# M365 register map
File version: 0.1
TOSHIBA Cortex-M3 MCU
CPU: 
Registers are 32-bit, read-write, reset 0x0 unless marked. A register's access mark holds for its fields unless they carry their own. Offsets are from the block's base; lines under a group give offsets from that group; [hi:lo] are bit positions; {n}, {i} and the like mark numbered series; 'fields as' and 'values as' point back to an identical list; <NAME> marks a mode.

## Memory map
0x40000000 DMAC size 0x28 — DMA Controller
0x40008000 UDFS size 0x24 — UDC2 AHB Bridge
0x40008200 UDFS2 size 0x8 — UDC2(USB -Spec2.0 Device contoller)
0x40050000 AD size 0x64 — Analog-to-Digital Converter (AD)
0x400C0000 PA size 0x8 — General Purpose Input_Output Port (PA)
0x400C0100 PB size 0x8 — General Purpose Input_Output Port (PB)
0x400C0200 PC size 0xC — General Purpose Input_Output Port (PC)
0x400C0300 PD size 0x8 — General Purpose Input_Output Port (PD)
0x400C0400 PE size 0xC — General Purpose Input_Output Port (PE)
0x400C0500 PF size 0x8 — General Purpose Input_Output Port (PF)
0x400C0600 PG size 0xC — General Purpose Input_Output Port (PG)
0x400C0700 PH size 0xC — General Purpose Input_Output Port (PH)
0x400C0800 PI size 0x8 — General Purpose Input_Output Port (PI)
0x400C0900 PJ size 0x8 — General Purpose Input_Output Port (PJ)
0x400C0A00 PK size 0x8 — General Purpose Input_Output Port (PK)
{0x400C4000+0x100*n} TB{n} size 0x34 (n=0..9) — 16-bit Timer_Event Counter (TB)
0x400E0000 SBI0 size 0x18 — Serial Bus Interface (SBI)
0x400E0100 SBI1 size 0x18 — Serial Bus Interface (SBI)
0x400E1000 SC0 size 0x38 — Serial Channel (SC)
0x400E1100 SC1 size 0x38 — Serial Channel (SC)
0x400F2000 WD size 0x8 — Watchdog Timer (WD)
0x400F3000 CG size 0x14 — Clock Generator (CG)
0x41FFF010 FC size 0x4 — Flash Control (FC)

## DMAC — DMA Controller
Base 0x40000000
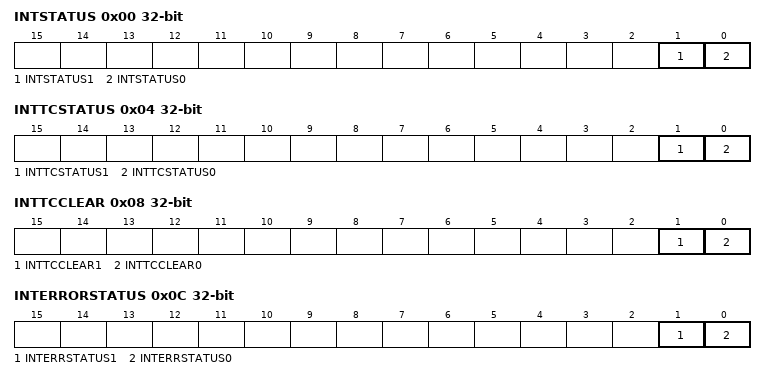
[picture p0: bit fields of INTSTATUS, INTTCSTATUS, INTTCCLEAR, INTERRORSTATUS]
0x00 INTSTATUS ro — DMAC Interrupt Status Register
  [1] INTSTATUS1, [0] INTSTATUS0
0x04 INTTCSTATUS ro — DMAC Interrupt Terminal Count Status Register
  [1] INTTCSTATUS1, [0] INTTCSTATUS0
0x08 INTTCCLEAR wo — DMAC Interrupt Terminal Count Clear Register
  [1] INTTCCLEAR1, [0] INTTCCLEAR0
0x0C INTERRORSTATUS ro — DMAC Interrupt Error Status Register
  [1] INTERRSTATUS1, [0] INTERRSTATUS0
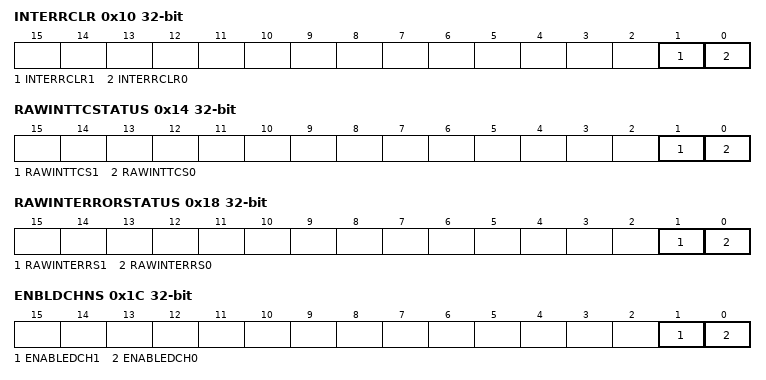
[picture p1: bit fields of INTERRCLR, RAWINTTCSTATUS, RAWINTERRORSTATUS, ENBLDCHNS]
0x10 INTERRCLR wo — DMAC Interrupt Error Clear Register
  [1] INTERRCLR1, [0] INTERRCLR0
0x14 RAWINTTCSTATUS ro — DMAC Raw Interrupt Terminal Count Status Register
  [1] RAWINTTCS1, [0] RAWINTTCS0
0x18 RAWINTERRORSTATUS ro — DMAC Raw Error Interrupt Status Register
  [1] RAWINTERRS1, [0] RAWINTERRS0
0x1C ENBLDCHNS ro — DMAC Enabled Channel Register
  [1] ENABLEDCH1, [0] ENABLEDCH0
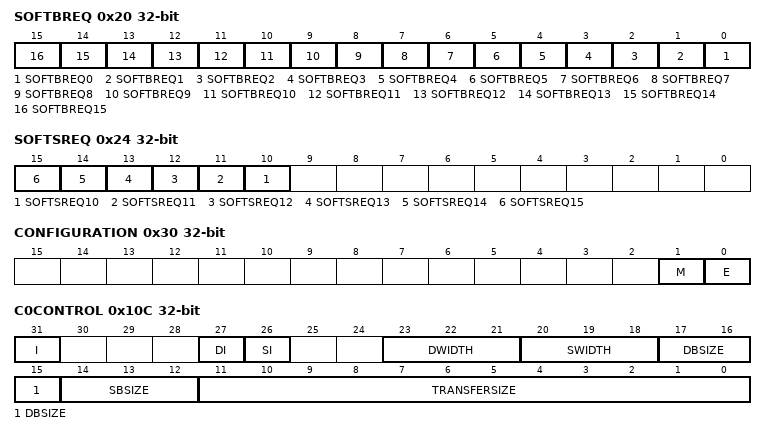
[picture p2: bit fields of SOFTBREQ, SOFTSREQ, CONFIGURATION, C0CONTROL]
0x20 SOFTBREQ — DMAC Software Burst Request Register
  [n] SOFTBREQ{n} (n=0..15)
0x24 SOFTSREQ — DMAC Software Single Request Register
  [n] SOFTSREQ{n} (n=10..15)
0x30 CONFIGURATION — DMAC Configuration Register
  [1] M, [0] E
0x100 C0SRCADDR — DMAC Channel0 Source Address Register
  [31:0] SRCADDR
0x104 C0DESTADDR — DMAC Channel0 Destination Address Register
  [31:0] DESTADDR
0x108 C0LLI — DMAC Channel0 Linked List Item Register
  [31:2] LLI
0x10C C0CONTROL — DMAC Channel0 Control Register
  [31] I, [27] DI, [26] SI, [23:21] DWIDTH, [20:18] SWIDTH, [17:15] DBSIZE, [14:12] SBSIZE, [11:0] TRANSFERSIZE
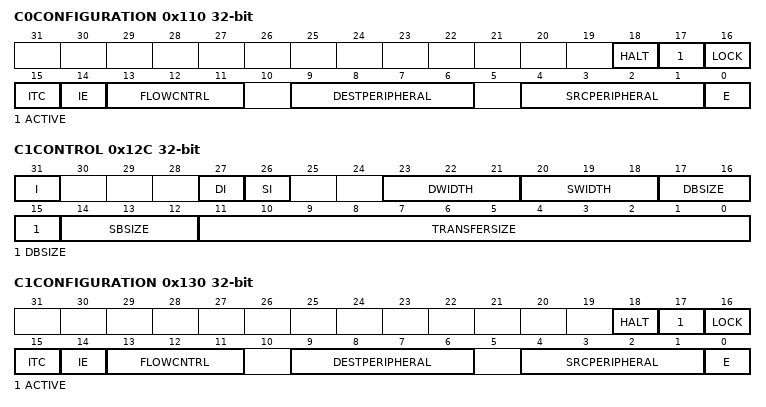
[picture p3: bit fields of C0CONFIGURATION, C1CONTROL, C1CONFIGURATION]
0x110 C0CONFIGURATION — DMAC Channel0 Configuration Register
  [18] HALT, [17] ACTIVE ro, [16] LOCK, [15] ITC, [14] IE, [13:11] FLOWCNTRL, [9:6] DESTPERIPHERAL, [4:1] SRCPERIPHERAL, [0] E
0x120 C1SRCADDR — DMAC Channel1 Source Address Register
  [31:0] SRCADDR
0x124 C1DESTADDR — DMAC Channel1 Destination Address Register
  [31:0] DESTADDR
0x128 C1LLI — DMAC Channel1 Linked List Item Register
  [31:1] LLI
0x12C C1CONTROL — DMAC Channel1 Control Register
  fields as C0CONTROL
0x130 C1CONFIGURATION — DMAC Channel1 Configuration Register
  fields as C0CONFIGURATION

## UDFS — UDC2 AHB Bridge
Base 0x40008000
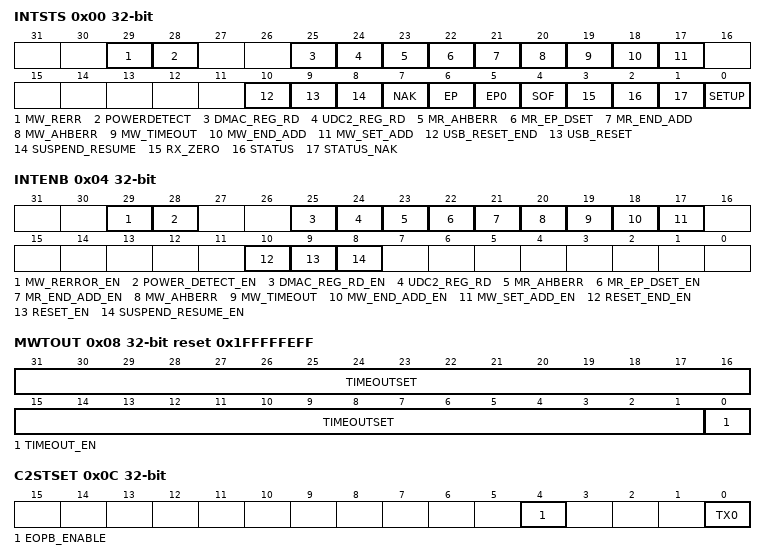
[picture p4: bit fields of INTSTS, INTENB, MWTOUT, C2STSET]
0x00 INTSTS — Interrupt Status Register
  [29] MW_RERR, [28] POWERDETECT, [25] DMAC_REG_RD, [24] UDC2_REG_RD, [23] MR_AHBERR, [22] MR_EP_DSET, [21] MR_END_ADD, [20] MW_AHBERR, [19] MW_TIMEOUT, [18] MW_END_ADD, [17] MW_SET_ADD, [10] USB_RESET_END, [9] USB_RESET, [8] SUSPEND_RESUME, [7] NAK ro, [6] EP ro, [5] EP0 ro, [4] SOF ro, [3] RX_ZERO ro, [2] STATUS ro, [1] STATUS_NAK ro, [0] SETUP ro
0x04 INTENB — Interrupt Enable Register
  [29] MW_RERROR_EN, [28] POWER_DETECT_EN, [25] DMAC_REG_RD_EN, [24] UDC2_REG_RD, [23] MR_AHBERR, [22] MR_EP_DSET_EN, [21] MR_END_ADD_EN, [20] MW_AHBERR, [19] MW_TIMEOUT, [18] MW_END_ADD_EN, [17] MW_SET_ADD_EN, [10] RESET_END_EN, [9] RESET_EN, [8] SUSPEND_RESUME_EN
0x08 MWTOUT reset 0x1FFFFFEFF — Master Write Timeout Register
  [31:1] TIMEOUTSET, [0] TIMEOUT_EN
0x0C C2STSET — UDC2 setting
  [4] EOPB_ENABLE, [0] TX0
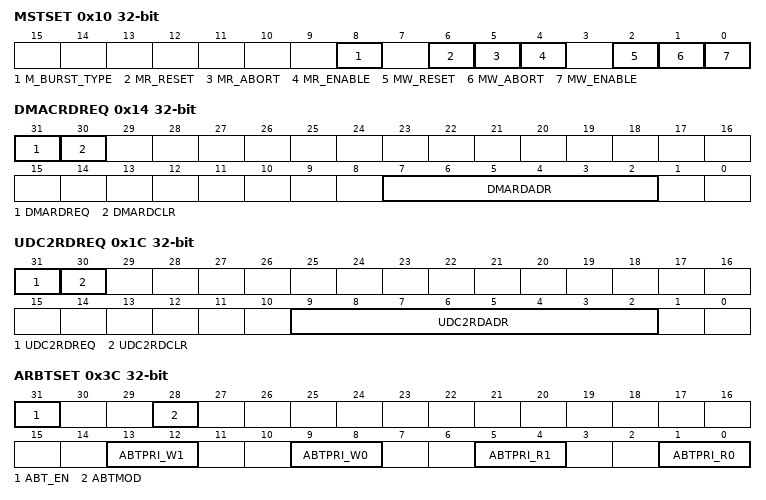
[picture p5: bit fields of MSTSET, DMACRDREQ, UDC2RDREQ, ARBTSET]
0x10 MSTSET — DMAC setting
  [8] M_BURST_TYPE, [6] MR_RESET, [5] MR_ABORT wo, [4] MR_ENABLE, [2] MW_RESET, [1] MW_ABORT wo, [0] MW_ENABLE
0x14 DMACRDREQ — DMAC Read request
  [31] DMARDREQ, [30] DMARDCLR, [7:2] DMARDADR
0x18 DMACRDVL ro — DMAC Read Value
  [31:0] DMARDDATA
0x1C UDC2RDREQ — UDC2 Read Request
  [31] UDC2RDREQ, [30] UDC2RDCLR, [9:2] UDC2RDADR
0x20 UDC2RDVL ro — UDC2 Read Value
  [31:0] UDC2RDATA
0x3C ARBTSET — Arbiter Setting
  [31] ABT_EN, [28] ABTMOD, [13:12] ABTPRI_W1, [9:8] ABTPRI_W0, [5:4] ABTPRI_R1, [1:0] ABTPRI_R0
0x40 MWSADR reset 0xFFFFFFFF — Master Write Start Address
0x44 MWEADR reset 0xFFFFFFFF — Master Write End Address
0x48 MWCADR ro reset 0xFFFFFFFF — Master Write Current Address
0x4C MWAHBADR ro reset 0xFFFFFFFF — Master Write AHB Address
0x50 MRSADR reset 0xFFFFFFFF — Master Read Start Address
0x54 MREADR reset 0xFFFFFFFF — Master Read End Address
0x58 MRCADR ro reset 0xFFFFFFFF — Master Read Current Address
0x5C MRAHBADR ro reset 0xFFFFFFFF — Master Read AHB Address
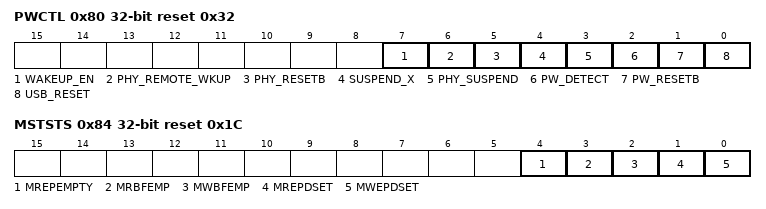
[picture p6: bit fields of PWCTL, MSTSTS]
0x80 PWCTL reset 0x32 — Power Detect Control
  [7] WAKEUP_EN, [6] PHY_REMOTE_WKUP, [5] PHY_RESETB, [4] SUSPEND_X ro, [3] PHY_SUSPEND, [2] PW_DETECT ro, [1] PW_RESETB, [0] USB_RESET ro
0x84 MSTSTS ro reset 0x1C — Master Status
  [4] MREPEMPTY, [3] MRBFEMP, [2] MWBFEMP, [1] MREPDSET, [0] MWEPDSET
0x88 TOUTCNT ro reset 0xFFFFFFFF — Timeout Count
  [31:0] TMOUTCNT
